# ESP32-C6 register map
Vendor: ESPRESSIF SYSTEMS (SHANGHAI) CO., LTD.; Series: ESP32 C-Series; File version: 2
CPU: RV32IMC r0p0, little endian, no MPU, no FPU, 4 interrupt priority bits
Address unit: 32 bits
Registers are 32-bit, read-write, reset 0x0 unless marked. A register's access mark holds for its fields unless they carry their own. Offsets are from the block's base; [hi:lo] are bit positions; {n}, {i} and the like mark numbered series.

## PAU — Peripheral PAU
Base 0x60093000
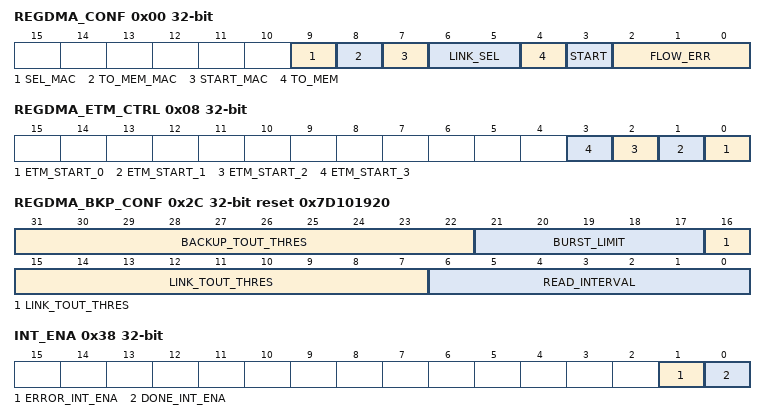
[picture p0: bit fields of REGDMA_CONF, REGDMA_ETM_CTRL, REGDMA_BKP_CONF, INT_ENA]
0x00 REGDMA_CONF access per field — Peri backup control register
  [9] SEL_MAC rw — mac hw/sw select
  [8] TO_MEM_MAC rw — mac sw backup direction(reg to mem / mem to reg)
  [7] START_MAC wo — mac sw backup start signal
  [6:5] LINK_SEL rw — Link select
  [4] TO_MEM rw — backup direction(reg to mem / mem to reg)
  [3] START wo — backup start signal
  [2:0] FLOW_ERR ro — backup error type
0x04 REGDMA_CLK_CONF — Clock control register
  [0] CLK_EN — clock enable
0x08 REGDMA_ETM_CTRL wo — ETM start ctrl reg
  [n] ETM_START_{n} (n=0..3) — etm_start_{n} reg
0x0C REGDMA_LINK_0_ADDR — link_0_addr
  [31:0] LINK_ADDR_0 — link_0_addr reg
{0xC+4i} REGDMA_LINK_{i}_ADDR (i=1..3) — Link_{i}_addr
  [31:0] LINK_ADDR_{i} — Link_{i}_addr reg
0x1C REGDMA_LINK_MAC_ADDR — Link_mac_addr
  [31:0] LINK_ADDR_MAC — Link_mac_addr reg
0x20 REGDMA_CURRENT_LINK_ADDR ro — current link addr
  [31:0] CURRENT_LINK_ADDR — current link addr reg
0x24 REGDMA_BACKUP_ADDR ro — Backup addr
  [31:0] BACKUP_ADDR — backup addr reg
0x28 REGDMA_MEM_ADDR ro — mem addr
  [31:0] MEM_ADDR — mem addr reg
0x2C REGDMA_BKP_CONF reset 0x7D101920 — backup config
  [31:22] BACKUP_TOUT_THRES — Backup timeout threshold
  [21:17] BURST_LIMIT
  [16:7] LINK_TOUT_THRES — link wait timeout threshold
  [6:0] READ_INTERVAL — Link read_interval
0x30 RETENTION_LINK_BASE — retention dma link base
  [26:0] LINK_BASE_ADDR
0x34 RETENTION_CFG reset 0xFFFFFFFF
  [31:0] RET_INV_CFG — retention inv scan out
0x38 INT_ENA — Read only register for error and done
  [1] ERROR_INT_ENA — error flag
  [0] DONE_INT_ENA — backup done flag
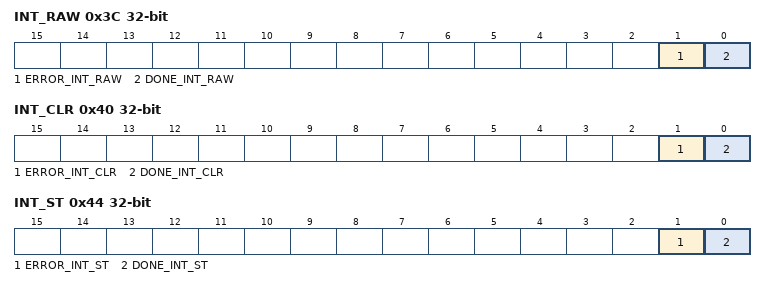
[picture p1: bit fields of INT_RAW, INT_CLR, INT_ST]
0x3C INT_RAW ro — Read only register for error and done
  [1] ERROR_INT_RAW — error flag
  [0] DONE_INT_RAW — backup done flag
0x40 INT_CLR wo — Read only register for error and done
  [1] ERROR_INT_CLR — error flag
  [0] DONE_INT_CLR — backup done flag
0x44 INT_ST ro — Read only register for error and done
  [1] ERROR_INT_ST — error flag
  [0] DONE_INT_ST — backup done flag
0x3FC DATE reset 0x2203070
  [27:0] DATE — REGDMA date information/ REGDMA version information.

## RNG — Hardware random number generator
Base 0x600B2800
0x08 DATA access not given — Random number data

## RSA — RSA (Rivest Shamir Adleman) Accelerator
Base 0x6008A000
{0x0+i} M_MEM[{i}] (i=0..15) 8-bit access not given — The memory that stores M
{0x200+i} Z_MEM[{i}] (i=0..15) 8-bit access not given — The memory that stores Z
{0x400+i} Y_MEM[{i}] (i=0..15) 8-bit access not given — The memory that stores Y
{0x600+i} X_MEM[{i}] (i=0..15) 8-bit access not given — The memory that stores X
0x800 M_PRIME — RSA M_prime register
  [31:0] M_PRIME — Those bits stores m'
0x804 MODE — RSA mode register
  [6:0] MODE — rsa mode (rsa length).
0x808 QUERY_CLEAN ro — RSA query clean register
  [0] QUERY_CLEAN
0x80C SET_START_MODEXP wo — RSA modular exponentiation trigger register.
  [0] SET_START_MODEXP — start modular exponentiation
0x810 SET_START_MODMULT wo — RSA modular multiplication trigger register.
  [0] SET_START_MODMULT — start modular multiplication
0x814 SET_START_MULT wo — RSA normal multiplication trigger register.
  [0] SET_START_MULT — start multiplicaiton
0x818 QUERY_IDLE ro — RSA query idle register
  [0] QUERY_IDLE — query rsa idle. 1'b0: busy, 1'b1: idle
0x81C INT_CLR wo — RSA interrupt clear register
  [0] CLEAR_INTERRUPT — set this bit to clear RSA interrupt.
0x820 CONSTANT_TIME reset 0x1 — RSA constant time option register
  [0] CONSTANT_TIME — Configure this bit to 0 for acceleration. 0: with acceleration, 1: without acceleration(defalut).
0x824 SEARCH_ENABLE — RSA search option
  [0] SEARCH_ENABLE — Configure this bit to 1 for acceleration. 1: with acceleration, 0: without acceleration(default). This option should be used together with RSA_SEARCH_POS.
0x828 SEARCH_POS — RSA search position configure register
  [11:0] SEARCH_POS — Configure this field to set search position. This field should be used together with RSA_SEARCH_ENABLE. The field is only meaningful when RSA_SEARCH_ENABLE is high.
0x82C INT_ENA — RSA interrupt enable register
  [0] INT_ENA — Set this bit to enable interrupt that occurs when rsa calculation is done. 1'b0: disable, 1'b1: enable(default).
0x830 DATE reset 0x20200618 — RSA version control register
  [29:0] DATE — rsa version information
